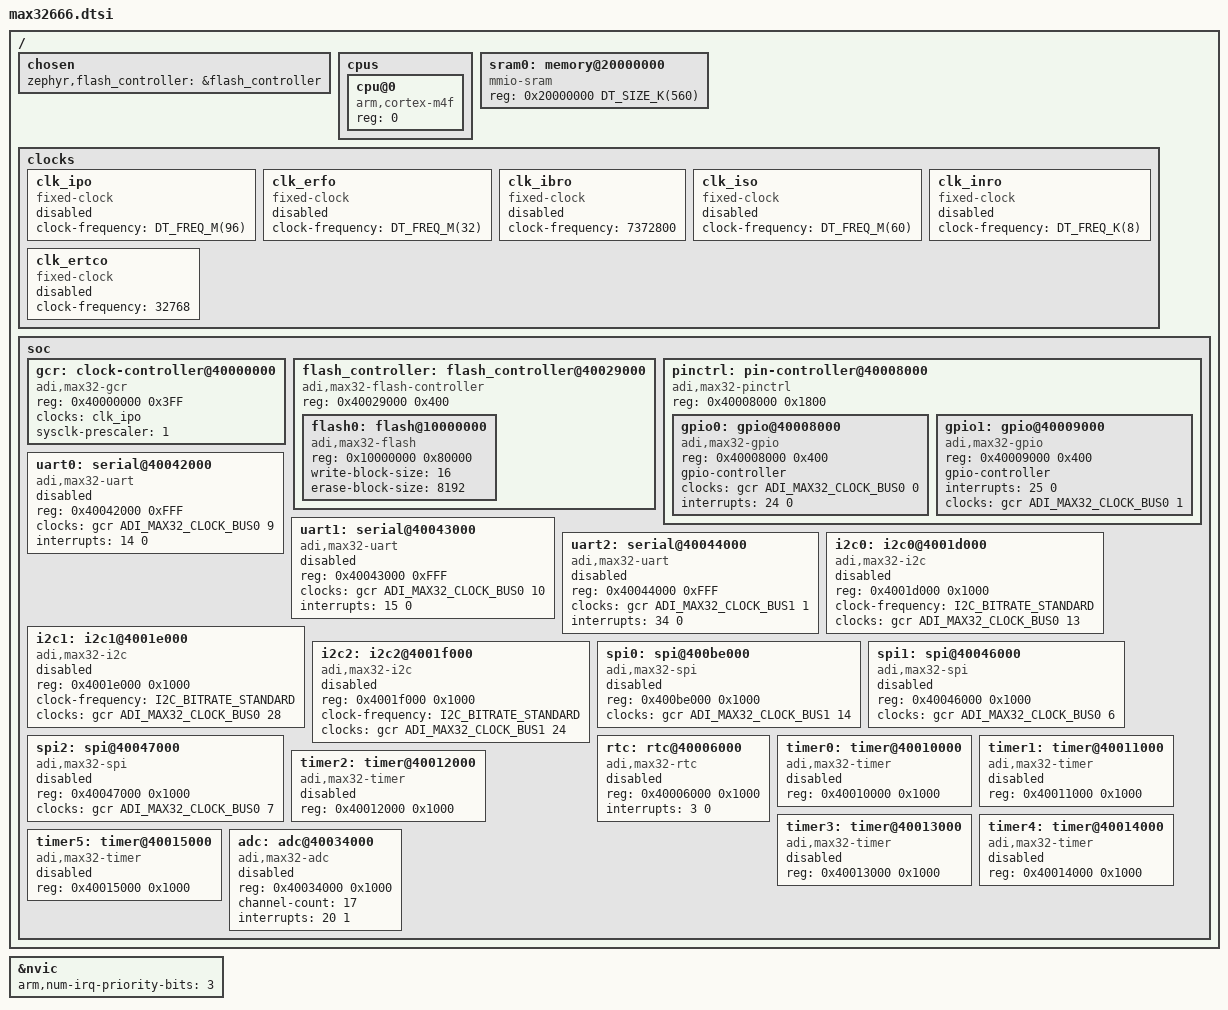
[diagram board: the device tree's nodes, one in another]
/*
 * Copyright (c) 2023 Analog Devices, Inc.
 *
 * SPDX-License-Identifier: Apache-2.0
 */

 #include <mem.h>
 #include <arm/armv7-m.dtsi>
 #include <zephyr/dt-bindings/i2c/i2c.h>
 #include <zephyr/dt-bindings/gpio/gpio.h>
 #include <zephyr/dt-bindings/pwm/pwm.h>
 #include <zephyr/dt-bindings/adc/adc.h>
 #include <zephyr/dt-bindings/clock/adi_max32_clock.h>

 #include <freq.h>

/ {
	chosen {
		 zephyr,flash_controller = &flash_controller;
	};

	cpus {
		#address-cells = <1>;
		#size-cells = <0>;

		cpu@0 {
			device_type = "cpu";
			compatible = "arm,cortex-m4f";
			reg = <0>;
		};
	};

	sram0: memory@20000000 {
		compatible = "mmio-sram";
		reg = <0x20000000 DT_SIZE_K(560)>;
	};

	clocks {
		clk_ipo: clk_ipo {
			compatible = "fixed-clock";
			#clock-cells = <0>;
			clock-frequency = <DT_FREQ_M(96)>;
			status = "disabled";
		};

		clk_erfo: clk_erfo {
			compatible = "fixed-clock";
			#clock-cells = <0>;
			clock-frequency = <DT_FREQ_M(32)>;
			status = "disabled";
		};

		clk_ibro: clk_ibro {
			compatible = "fixed-clock";
			#clock-cells = <0>;
			clock-frequency = < 7372800 >;
			status = "disabled";
		};

		clk_iso: clk_iso {
			compatible = "fixed-clock";
			#clock-cells = <0>;
			clock-frequency = <DT_FREQ_M(60)>;
			status = "disabled";
		};

		clk_inro: clk_inro {
			compatible = "fixed-clock";
			#clock-cells = <0>;
			clock-frequency = < DT_FREQ_K(8) >;
			status = "disabled";
		};

		clk_ertco: clk_ertco {
			compatible = "fixed-clock";
			#clock-cells = <0>;
			clock-frequency = < 32768 >;
			status = "disabled";
		};
	 };

	soc {
		gcr: clock-controller@40000000 {
			reg = <0x40000000 0x3FF>;
			compatible = "adi,max32-gcr";
			#clock-cells = <2>;
			clocks = <&clk_ipo>;
			sysclk-prescaler = <1>;
		};

		flash_controller: flash_controller@40029000 {
			compatible = "adi,max32-flash-controller";
			reg = <0x40029000 0x400>;

			#address-cells = <1>;
			#size-cells = <1>;

			flash0: flash@10000000 {
				compatible = "adi,max32-flash", "soc-nv-flash";
				reg = <0x10000000 0x80000>;
				write-block-size = <16>;
				erase-block-size = <8192>;
				/* maximum erase time for a 2K sector */
				//max-erase-time = <40>;
			};
		};

		pinctrl: pin-controller@40008000 {
			compatible = "adi,max32-pinctrl";
			#address-cells = <1>;
			#size-cells = <1>;
			reg = <0x40008000 0x1800>;

			gpio0: gpio@40008000 {
				reg = <0x40008000 0x400>;
				compatible = "adi,max32-gpio";
				gpio-controller;
				#gpio-cells = <2>;
				clocks = <&gcr ADI_MAX32_CLOCK_BUS0 0>;
				interrupts = <24 0>;
				status = "okay";
			};

			gpio1: gpio@40009000 {
				reg = <0x40009000 0x400>;
				compatible = "adi,max32-gpio";
				gpio-controller;
				#gpio-cells = <2>;
				interrupts = <25 0>;
				clocks = <&gcr ADI_MAX32_CLOCK_BUS0 1>;
				status = "okay";
			};
		};

		uart0: serial@40042000 {
			compatible = "adi,max32-uart";
			reg = <0x40042000 0xFFF>;
			clocks = <&gcr ADI_MAX32_CLOCK_BUS0 9>;
			interrupts = <14 0>;
			status = "disabled";
		};
		uart1: serial@40043000 {
			compatible = "adi,max32-uart";
			reg = <0x40043000 0xFFF>;
			clocks = <&gcr ADI_MAX32_CLOCK_BUS0 10>;
			interrupts = <15 0>;
			status = "disabled";
		};
		uart2: serial@40044000 {
			compatible = "adi,max32-uart";
			reg = <0x40044000 0xFFF>;
			clocks = <&gcr ADI_MAX32_CLOCK_BUS1 1>;
			interrupts = <34 0>;
			status = "disabled";
		};

		i2c0: i2c0@4001d000 {
			compatible = "adi,max32-i2c";
			reg = <0x4001d000 0x1000>;
			#address-cells = <1>;
			#size-cells = <0>;
			clock-frequency = <I2C_BITRATE_STANDARD>;
			clocks = <&gcr ADI_MAX32_CLOCK_BUS0 13>;
			status = "disabled";
		};

		i2c1: i2c1@4001e000 {
			compatible = "adi,max32-i2c";
			reg = <0x4001e000 0x1000>;
			#address-cells = <1>;
			#size-cells = <0>;
			clock-frequency = <I2C_BITRATE_STANDARD>;
			clocks = <&gcr ADI_MAX32_CLOCK_BUS0 28>;
			status = "disabled";
		};

		i2c2: i2c2@4001f000 {
			compatible = "adi,max32-i2c";
			reg = <0x4001f000 0x1000>;
			#address-cells = <1>;
			#size-cells = <0>;
			clock-frequency = <I2C_BITRATE_STANDARD>;
			clocks = <&gcr ADI_MAX32_CLOCK_BUS1 24>;
			status = "disabled";
		};

		spi0: spi@400be000 {
			compatible = "adi,max32-spi";
			reg = <0x400be000 0x1000>;
			#address-cells = <1>;
			#size-cells = <0>;
			clocks = <&gcr ADI_MAX32_CLOCK_BUS1 14>;
			status = "disabled";
		};

		spi1: spi@40046000 {
			compatible = "adi,max32-spi";
			reg = <0x40046000 0x1000>;
			#address-cells = <1>;
			#size-cells = <0>;
			clocks = <&gcr ADI_MAX32_CLOCK_BUS0 6>;
			status = "disabled";
		};

		spi2: spi@40047000 {
			compatible = "adi,max32-spi";
			reg = <0x40047000 0x1000>;
			#address-cells = <1>;
			#size-cells = <0>;
			clocks = <&gcr ADI_MAX32_CLOCK_BUS0 7>;
			status = "disabled";
		};
		rtc: rtc@40006000 {
			compatible = "adi,max32-rtc";
			reg = <0x40006000 0x1000>;
			interrupts = <3 0>;
			status = "disabled";
		};

		timer0: timer@40010000 {
			compatible = "adi,max32-timer";
			reg = <0x40010000 0x1000>;
			status = "disabled";
		};

		timer1: timer@40011000 {
			compatible = "adi,max32-timer";
			reg = <0x40011000 0x1000>;
			status = "disabled";
		};

		timer2: timer@40012000 {
			compatible = "adi,max32-timer";
			reg = <0x40012000 0x1000>;
			status = "disabled";
		};

		timer3: timer@40013000 {
			compatible = "adi,max32-timer";
			reg = <0x40013000 0x1000>;
			status = "disabled";
		};

		timer4: timer@40014000 {
			compatible = "adi,max32-timer";
			reg = <0x40014000 0x1000>;
			status = "disabled";
		};

		timer5: timer@40015000 {
			compatible = "adi,max32-timer";
			reg = <0x40015000 0x1000>;
			status = "disabled";
		};

		adc: adc@40034000 {
			compatible = "adi,max32-adc";
			reg = <0x40034000 0x1000>;
			channel-count = <17>;
			#io-channel-cells = <1>;
			status = "disabled";
			interrupts = <20 1>;
		};
	};
};

&nvic {
	arm,num-irq-priority-bits = <3>;
};
